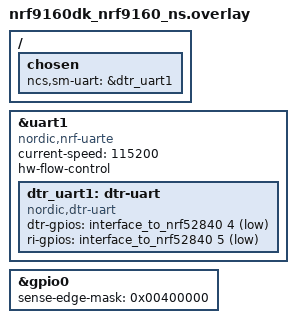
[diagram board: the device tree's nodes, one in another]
/*
 * Copyright (c) 2026 Golioth, Inc.
 *
 * SPDX-License-Identifier: LicenseRef-Nordic-5-Clause
 */

#include <nrf9160/nrf9160dk_uart1_on_if0_3.dtsi>

/ {
	chosen {
		ncs,sm-uart = &dtr_uart1;
	};
};

&uart1 {
	compatible = "nordic,nrf-uarte";
        current-speed = <115200>;
        hw-flow-control;
	status = "okay";

	dtr_uart1: dtr-uart {
		compatible = "nordic,dtr-uart";
		dtr-gpios = <&interface_to_nrf52840 4 (GPIO_PULL_DOWN | GPIO_ACTIVE_LOW)>;
		ri-gpios = <&interface_to_nrf52840 5 (GPIO_ACTIVE_LOW)>;
		status = "okay";
	};
};

&gpio0 {
	status = "okay";
	/* Use PORT event for DTR (22) pin to save power */
	sense-edge-mask = <0x00400000>;
};
